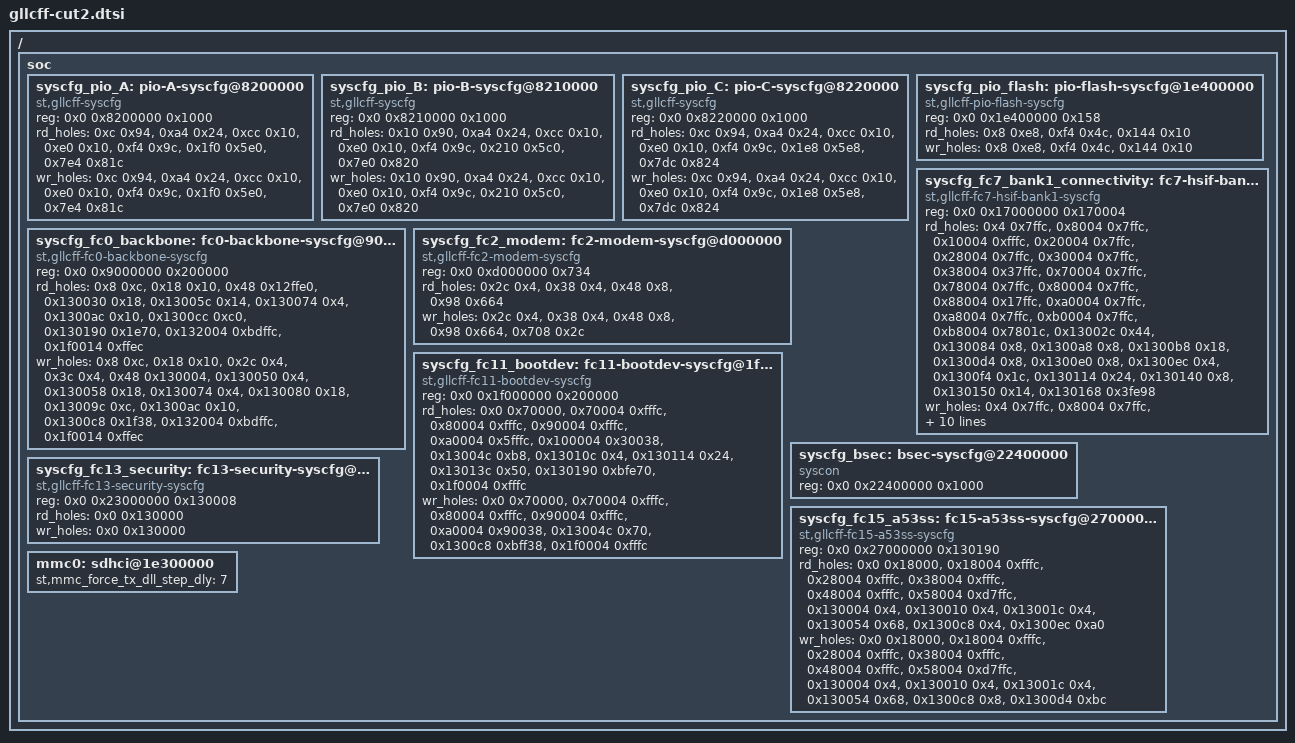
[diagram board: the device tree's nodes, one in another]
/*
 * Copyright (C) 2018 STMicroelectronics (R&D) Limited.
 * Author: Nicolas Toromanoff <nicolas.toromanoff@st.com>
 *
 * This program is free software; you can redistribute it and/or modify
 * it under the terms of the GNU General Public License version 2 as
 * published by the Free Software Foundation.
 */
#include <dt-bindings/phy/phy.h>
#include <dt-bindings/interrupt-controller/arm-gic.h>
#include <dt-bindings/reset/gllcff-resets.h>
#include <dt-bindings/soc/gllcff-syscfg.h>
#include <dt-bindings/soc/sti-flashss.h>
#include "gllcff-clocks.dtsi"
#include "gllcff-pinctrl-cut2.dtsi"
#include "gllcff-ibi-cut2.dtsi"
#include "gllcff-allcut.dtsi"
#include "gllcff-sms.dtsi"

/ {
	soc {
		/*generated 2018-12-11 17:46:27.627644 from Cut2 assy3.3 computing_platform_registers_without_sxips.xml*/
		/* BACKBONE_SYSCFG_PIO_A */
		syscfg_pio_A: pio-A-syscfg@8200000 {
			compatible = "st,gllcff-syscfg", "syscon";
			reg = <0x0 0x8200000 0x1000>;
			rd_holes = <0xc 0x94>,
				   <0xa4 0x24>,
				   <0xcc 0x10>,
				   <0xe0 0x10>,
				   <0xf4 0x9c>,
				   <0x1f0 0x5e0>,
				   <0x7e4 0x81c>;
			wr_holes = <0xc 0x94>,
				   <0xa4 0x24>,
				   <0xcc 0x10>,
				   <0xe0 0x10>,
				   <0xf4 0x9c>,
				   <0x1f0 0x5e0>,
				   <0x7e4 0x81c>;
		};

		/* BACKBONE_SYSCFG_PIO_B */
		syscfg_pio_B: pio-B-syscfg@8210000 {
			compatible = "st,gllcff-syscfg", "syscon";
			reg = <0x0 0x8210000 0x1000>;
			rd_holes = <0x10 0x90>,
				   <0xa4 0x24>,
				   <0xcc 0x10>,
				   <0xe0 0x10>,
				   <0xf4 0x9c>,
				   <0x210 0x5c0>,
				   <0x7e0 0x820>;
			wr_holes = <0x10 0x90>,
				   <0xa4 0x24>,
				   <0xcc 0x10>,
				   <0xe0 0x10>,
				   <0xf4 0x9c>,
				   <0x210 0x5c0>,
				   <0x7e0 0x820>;
		};

		/* BACKBONE_SYSCFG_PIO_C */
		syscfg_pio_C: pio-C-syscfg@8220000 {
			compatible = "st,gllcff-syscfg", "syscon";
			reg = <0x0 0x8220000 0x1000>;
			rd_holes = <0xc 0x94>,
				   <0xa4 0x24>,
				   <0xcc 0x10>,
				   <0xe0 0x10>,
				   <0xf4 0x9c>,
				   <0x1e8 0x5e8>,
				   <0x7dc 0x824>;
			wr_holes = <0xc 0x94>,
				   <0xa4 0x24>,
				   <0xcc 0x10>,
				   <0xe0 0x10>,
				   <0xf4 0x9c>,
				   <0x1e8 0x5e8>,
				   <0x7dc 0x824>;
		};

		/* BOOTDEV_FLASH_PIOMUX_0 */
		syscfg_pio_flash: pio-flash-syscfg@1e400000 {
			compatible = "st,gllcff-pio-flash-syscfg", "syscon";
			reg = <0x0 0x1e400000 0x158>;
			rd_holes = <0x8 0xe8>,
				   <0xf4 0x4c>,
				   <0x144 0x10>;
			wr_holes = <0x8 0xe8>,
				   <0xf4 0x4c>,
				   <0x144 0x10>;
		};

		/* BACKBONE_SYSCFG_000_799 */
		syscfg_fc0_backbone: fc0-backbone-syscfg@9000000 {
			compatible = "st,gllcff-fc0-backbone-syscfg", "syscon";
			reg = <0x0 0x9000000 0x200000>;
			rd_holes = <0x8 0xc>,
				   <0x18 0x10>,
				   <0x48 0x12ffe0>,
				   <0x130030 0x18>,
				   <0x13005c 0x14>,
				   <0x130074 0x4>,
				   <0x1300ac 0x10>,
				   <0x1300cc 0xc0>,
				   <0x130190 0x1e70>,
				   <0x132004 0xbdffc>,
				   <0x1f0014 0xffec>;
			wr_holes = <0x8 0xc>,
				   <0x18 0x10>,
				   <0x2c 0x4>,
				   <0x3c 0x4>,
				   <0x48 0x130004>,
				   <0x130050 0x4>,
				   <0x130058 0x18>,
				   <0x130074 0x4>,
				   <0x130080 0x18>,
				   <0x13009c 0xc>,
				   <0x1300ac 0x10>,
				   <0x1300c8 0x1f38>,
				   <0x132004 0xbdffc>,
				   <0x1f0014 0xffec>;
		};

		/* MODEM_SYSCFG_2000_2799_SYSCFG_2000_2799 */
		syscfg_fc2_modem: fc2-modem-syscfg@d000000 {
			compatible = "st,gllcff-fc2-modem-syscfg", "syscon";
			reg = <0x0 0xd000000 0x734>;
			rd_holes = <0x2c 0x4>,
				   <0x38 0x4>,
				   <0x48 0x8>,
				   <0x98 0x664>;
			wr_holes = <0x2c 0x4>,
				   <0x38 0x4>,
				   <0x48 0x8>,
				   <0x98 0x664>,
				   <0x708 0x2c>;
		};

		/* CONNECTIVITY_SYSCFG_7000_7799 */
		syscfg_fc7_bank1_connectivity: fc7-hsif-bank1-syscfg@17000000 {
			compatible = "st,gllcff-fc7-hsif-bank1-syscfg", "syscon";
			reg = <0x0 0x17000000 0x170004>;
			rd_holes = <0x4 0x7ffc>,
				   <0x8004 0x7ffc>,
				   <0x10004 0xfffc>,
				   <0x20004 0x7ffc>,
				   <0x28004 0x7ffc>,
				   <0x30004 0x7ffc>,
				   <0x38004 0x37ffc>,
				   <0x70004 0x7ffc>,
				   <0x78004 0x7ffc>,
				   <0x80004 0x7ffc>,
				   <0x88004 0x17ffc>,
				   <0xa0004 0x7ffc>,
				   <0xa8004 0x7ffc>,
				   <0xb0004 0x7ffc>,
				   <0xb8004 0x7801c>,
				   <0x13002c 0x44>,
				   <0x130084 0x8>,
				   <0x1300a8 0x8>,
				   <0x1300b8 0x18>,
				   <0x1300d4 0x8>,
				   <0x1300e0 0x8>,
				   <0x1300ec 0x4>,
				   <0x1300f4 0x1c>,
				   <0x130114 0x24>,
				   <0x130140 0x8>,
				   <0x130150 0x14>,
				   <0x130168 0x3fe98>;
			wr_holes = <0x4 0x7ffc>,
				   <0x8004 0x7ffc>,
				   <0x10004 0xfffc>,
				   <0x20004 0x7ffc>,
				   <0x28004 0x7ffc>,
				   <0x30004 0x7ffc>,
				   <0x38004 0x37ffc>,
				   <0x70004 0x7ffc>,
				   <0x78004 0x7ffc>,
				   <0x80004 0x7ffc>,
				   <0x88004 0x17ffc>,
				   <0xa0004 0x7ffc>,
				   <0xa8004 0x7ffc>,
				   <0xb0004 0x7ffc>,
				   <0xb8004 0x7801c>,
				   <0x13002c 0x44>,
				   <0x130084 0x8>,
				   <0x1300a8 0x8>,
				   <0x1300b8 0x4>,
				   <0x1300c8 0xc>,
				   <0x1300dc 0x4>,
				   <0x1300e8 0x4>,
				   <0x1300f4 0x3ff0c>;
		};

		/* BOOTDEV_SYSCFG_11000_11799_SYSCFG_11000_11799 */
		syscfg_fc11_bootdev: fc11-bootdev-syscfg@1f000000 {
			compatible = "st,gllcff-fc11-bootdev-syscfg", "syscon";
			reg = <0x0 0x1f000000 0x200000>;
			rd_holes = <0x0 0x70000>,
				   <0x70004 0xfffc>,
				   <0x80004 0xfffc>,
				   <0x90004 0xfffc>,
				   <0xa0004 0x5fffc>,
				   <0x100004 0x30038>,
				   <0x13004c 0xb8>,
				   <0x13010c 0x4>,
				   <0x130114 0x24>,
				   <0x13013c 0x50>,
				   <0x130190 0xbfe70>,
				   <0x1f0004 0xfffc>;
			wr_holes = <0x0 0x70000>,
				   <0x70004 0xfffc>,
				   <0x80004 0xfffc>,
				   <0x90004 0xfffc>,
				   <0xa0004 0x90038>,
				   <0x13004c 0x70>,
				   <0x1300c8 0xbff38>,
				   <0x1f0004 0xfffc>;
		};

		/* SECURITY_BSEC */
		syscfg_bsec: bsec-syscfg@22400000 {
			compatible = "syscon";
			reg = <0x0 0x22400000 0x1000>;
		};

		/* SECURITY_SYSCFG_13000_13799 */
		syscfg_fc13_security: fc13-security-syscfg@23000000 {
			compatible = "st,gllcff-fc13-security-syscfg", "syscon";
			reg = <0x0 0x23000000 0x130008>;
			rd_holes = <0x0 0x130000>;
			wr_holes = <0x0 0x130000>;
		};

		/* A53SS_SYSCFG_15000_15799 */
		syscfg_fc15_a53ss: fc15-a53ss-syscfg@27000000 {
			compatible = "st,gllcff-fc15-a53ss-syscfg", "syscon";
			reg = <0x0 0x27000000 0x130190>;
			rd_holes = <0x0 0x18000>,
				   <0x18004 0xfffc>,
				   <0x28004 0xfffc>,
				   <0x38004 0xfffc>,
				   <0x48004 0xfffc>,
				   <0x58004 0xd7ffc>,
				   <0x130004 0x4>,
				   <0x130010 0x4>,
				   <0x13001c 0x4>,
				   <0x130054 0x68>,
				   <0x1300c8 0x4>,
				   <0x1300ec 0xa0>;
			wr_holes = <0x0 0x18000>,
				   <0x18004 0xfffc>,
				   <0x28004 0xfffc>,
				   <0x38004 0xfffc>,
				   <0x48004 0xfffc>,
				   <0x58004 0xd7ffc>,
				   <0x130004 0x4>,
				   <0x130010 0x4>,
				   <0x13001c 0x4>,
				   <0x130054 0x68>,
				   <0x1300c8 0x8>,
				   <0x1300d4 0xbc>;
		};

		mmc0: sdhci@1e300000 {
			st,mmc_force_tx_dll_step_dly = <7>;
		};
	};
};
